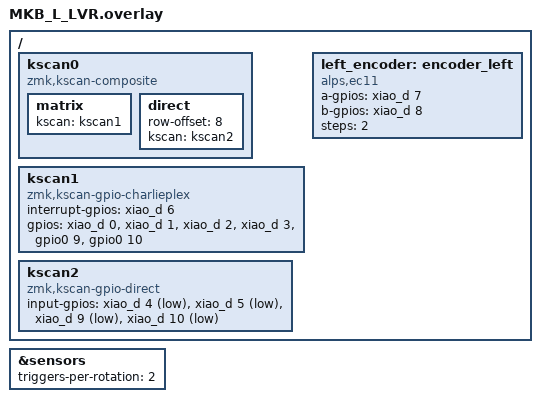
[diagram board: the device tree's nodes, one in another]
#include <zephyr/dt-bindings/input/input-event-codes.h>
#include <input/processors.dtsi>
#include <dt-bindings/zmk/input_transform.h>
#include <dt-bindings/zmk/keys.h>
#include "MKB_L_Base.dtsi"

/delete-node/ &kscan0;

/ {
   kscan0: kscan0 {
      compatible = "zmk,kscan-composite";
      matrix {
         kscan = <&kscan1>;
      };
      
      direct {
         row-offset = <8>;
         kscan = <&kscan2>;
      };
   };

   kscan1: kscan1 {
      compatible = "zmk,kscan-gpio-charlieplex";
      interrupt-gpios = <&xiao_d 6 (GPIO_ACTIVE_HIGH)>;
      gpios
         = <&xiao_d  0 (GPIO_ACTIVE_HIGH)>
         , <&xiao_d  1 (GPIO_ACTIVE_HIGH)>
         , <&xiao_d  2 (GPIO_ACTIVE_HIGH)>
         , <&xiao_d  3 (GPIO_ACTIVE_HIGH)>
         , <&gpio0   9 (GPIO_ACTIVE_HIGH)>
         , <&gpio0  10 (GPIO_ACTIVE_HIGH)>
         ;
   };

   kscan2: kscan2 {
      compatible = "zmk,kscan-gpio-direct";
      input-gpios
         = <&xiao_d 4 (GPIO_ACTIVE_LOW)>
         , <&xiao_d 5 (GPIO_ACTIVE_LOW)>
         , <&xiao_d 9 (GPIO_ACTIVE_LOW)>
         , <&xiao_d 10 (GPIO_ACTIVE_LOW)>
         ;
   };
   
   left_encoder: encoder_left {
      compatible = "alps,ec11";
      a-gpios = <&xiao_d 7 (GPIO_ACTIVE_HIGH | GPIO_PULL_UP)>;
      b-gpios = <&xiao_d 8 (GPIO_ACTIVE_HIGH | GPIO_PULL_UP)>;
      steps = <2>;
      status = "disabled";
   };
};
        
&sensors {
    triggers-per-rotation = <2>;
};

&left_encoder {
    status = "okay";
};
